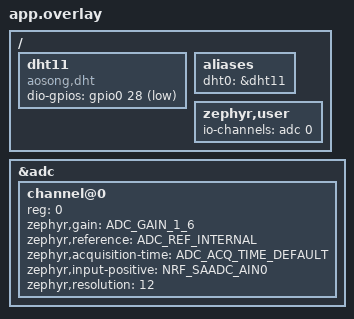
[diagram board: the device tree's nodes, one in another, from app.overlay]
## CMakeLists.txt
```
cmake_minimum_required(VERSION 3.20.0)

find_package(Zephyr REQUIRED HINTS $ENV{ZEPHYR_BASE})
project(sensor_node)

target_include_directories(app PRIVATE include)

target_sources(app PRIVATE
    src/main.c
    src/dht11_sensor.c
    src/sensor_monitor.c
    src/alert.c
    src/mq2_sensor.c
    src/alert_logic.c
)
```

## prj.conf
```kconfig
CONFIG_STDOUT_CONSOLE=y
CONFIG_SENSOR=y
CONFIG_GPIO=y
CONFIG_CBPRINTF_FP_SUPPORT=y
CONFIG_ADC=y
```

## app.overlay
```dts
#include <zephyr/dt-bindings/gpio/gpio.h>
#include <zephyr/dt-bindings/adc/adc.h>

/ {
    dht11: dht11 {
        compatible = "aosong,dht";
        status = "okay";
        dio-gpios = <&gpio0 28 GPIO_ACTIVE_LOW>;
    };

    aliases {
        dht0 = &dht11;
    };

    zephyr,user {
        io-channels = <&adc 0>;
    };
};

&adc {
    status = "okay";

    #address-cells = <1>;
    #size-cells = <0>;

    channel@0 {
        reg = <0>;
        zephyr,gain = "ADC_GAIN_1_6";
        zephyr,reference = "ADC_REF_INTERNAL";
        zephyr,acquisition-time = <ADC_ACQ_TIME_DEFAULT>;
        zephyr,input-positive = <NRF_SAADC_AIN0>;
        zephyr,resolution = <12>;
    };
};
```

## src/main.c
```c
#include <zephyr/kernel.h>
#include <zephyr/sys/printk.h>

int main(void)
{
    return 0;
}
```

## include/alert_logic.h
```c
#ifndef ALERT_LOGIC_H
#define ALERT_LOGIC_H

#include <stdbool.h>
#include "sensor_data.h"

enum alert_level {
    ALERT_NORMAL,
    ALERT_WARNING,
    ALERT_CRITICAL,
    ALERT_UNKNOWN
};

struct alert_result {
    enum alert_level level;

    bool high_temperature;
    bool extreme_temperature;
    bool high_gas;
    bool extreme_gas;
    bool flame_detected;
    bool assessment_complete;
};

struct alert_result evaluate_alert(
    const struct sensor_data *data
);

#endif
```

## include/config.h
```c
#ifndef APP_CONFIG_H
#define APP_CONFIG_H

/* Sensor sampling */
#define SENSOR_INTERVAL_SECONDS 10

#define MQ2_COUNTER 20
#define MQ2_DELAY 20
#define MQ2_MINIMUM_VALID_RFEADINGS 15

/* Temperature thresholds (Celsius) */
#define TEMP_HIGH_THRESHOLD 35.0
#define TEMP_EXTREME_THRESHOLD 55.0

/* Sensor error values */
#define DHT_ERROR_VALUE -1000.0
#define MQ2_ERROR_VALUE -1

/* MQ-2 thresholds (raw ADC values - experimental) */
#define MQ2_HIGH_THRESHOLD 250
#define MQ2_EXTREME_THRESHOLD 400

/* Flame detection*/
#define FLAME_ERROR_VALUE -1
#define FLAME_NOT_DETECTED 0
#define FLAME_DETECTED 1

#endif
```

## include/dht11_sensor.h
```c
#ifndef DHT11_SENSOR_H
#define DHT11_SENSOR_H

#include "sensor_data.h"

int dht11_read(struct sensor_data *data);

#endif
```

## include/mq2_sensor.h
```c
#ifndef MQ2_SENSOR_H
#define MQ2_SENSOR_H

int mq2_init(void);
int mq2_read(int *raw_value);

#endif
```

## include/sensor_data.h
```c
#ifndef SENSOR_DATA_H
#define SENSOR_DATA_H

#include <zephyr/kernel.h>

struct sensor_data {
    double temperature;
    double humidity;
    int mq2_raw;
    int flame_detected;
};

extern struct k_msgq sensor_queue;

#endif
```

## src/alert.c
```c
#include <zephyr/kernel.h>
#include <zephyr/sys/printk.h>

#include "sensor_data.h"
#include "alert_logic.h"
#include "config.h"

void alert_thread(void)
{
    struct sensor_data data;

    while (1) {
        if (k_msgq_get(&sensor_queue, &data, K_FOREVER) != 0) {
            continue;
        }

        bool dht_ok = (data.temperature != DHT_ERROR_VALUE);
        bool mq2_ok = (data.mq2_raw != MQ2_ERROR_VALUE);
        bool flame_ok =
            (data.flame_detected != FLAME_ERROR_VALUE);
        
            struct alert_result result = evaluate_alert(&data);

        const char *status;

        switch (result.level) {
        case ALERT_NORMAL:
            status = "NORMAL";
            break;
        case ALERT_WARNING:
            status = "WARNING";
            break;
        case ALERT_CRITICAL:
            status = "CRITICAL";
            break;
        default:
            status = "UNKNOWN";
            break;
        }

        /* Display sensor measurements */
        if (dht_ok) {
            printk("🌡️:%.2f 💧:%.2f ",
                   data.temperature, data.humidity);
        } else {
            printk("🌡️:N/A 💧:N/A ");
        }

        if (mq2_ok) {
            printk("💨:%d ", data.mq2_raw);
        } else {
            printk("💨:N/A ");
        }

        if (flame_ok) {
            printk("🔥:%d ", data.flame_detected);
        } else {
            printk("🔥:N/A ");
        }

        printk("S:%s R:", status);

        /* Display alert reasons */
        bool has_reason = false;

        if (result.extreme_temperature) {
            printk("EXTREME_TEMP");
            has_reason = true;
        } else if (result.high_temperature) {
            printk("HIGH_TEMP");
            has_reason = true;
        }

        if (result.extreme_gas) {
            printk("%sEXTREME_GAS", has_reason ? "," : "");
            has_reason = true;
        } else if (result.high_gas) {
            printk("%sHIGH_GAS", has_reason ? "," : "");
            has_reason = true;
        }

        if (result.flame_detected) {
            printk("%sFLAME", has_reason ? "," : "");
            has_reason = true;
        }

        if (!has_reason) {
            printk("NONE");
        }

        printk("\n");
    }
}

K_THREAD_DEFINE(alert_tid, 1024, alert_thread,
                NULL, NULL, NULL, 5, 0, 0);
```

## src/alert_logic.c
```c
#include "alert_logic.h"
#include "config.h"

struct alert_result evaluate_alert(
    const struct sensor_data *data)
{
    struct alert_result result = {
        .level = ALERT_UNKNOWN,
        .assessment_complete = false
    };

    /* Temperature */
    if (data->temperature != DHT_ERROR_VALUE) {
        result.high_temperature =
            data->temperature >= TEMP_HIGH_THRESHOLD;

        result.extreme_temperature =
            data->temperature >= TEMP_EXTREME_THRESHOLD;
    }

    /* Gas */
    if (data->mq2_raw != MQ2_ERROR_VALUE) {
        result.high_gas =
            data->mq2_raw >= MQ2_HIGH_THRESHOLD;

        result.extreme_gas =
            data->mq2_raw >= MQ2_EXTREME_THRESHOLD;
    }

    /* Flame */
    result.flame_detected =
        (data->flame_detected == FLAME_DETECTED);

    /* Check if all sensors provided valid measurements */
    result.assessment_complete =
        (data->temperature != DHT_ERROR_VALUE) &&
        (data->mq2_raw != MQ2_ERROR_VALUE) &&
        (data->flame_detected == FLAME_NOT_DETECTED ||
         data->flame_detected == FLAME_DETECTED);

    /* Count distinct hazard categories */
    int danger_count =
        (result.high_temperature || result.extreme_temperature) +
        (result.high_gas || result.extreme_gas) +
        result.flame_detected;

    /* Determine alert level */
    if (result.flame_detected || danger_count >= 2) {
        result.level = ALERT_CRITICAL;
    } else if (danger_count == 1) {
        result.level = ALERT_WARNING;
    } else if (result.assessment_complete) {
        result.level = ALERT_NORMAL;
    }

    return result;
}
```

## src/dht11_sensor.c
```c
#include <zephyr/device.h>
#include <zephyr/drivers/sensor.h>
#include <errno.h>

#include "dht11_sensor.h"
#include "sensor_data.h"

#define DHT_NODE DT_ALIAS(dht0)

int dht11_read(struct sensor_data *data)
{
    const struct device *dht = DEVICE_DT_GET(DHT_NODE);
    struct sensor_value temp, hum;

    if (!device_is_ready(dht)) {
        return -ENODEV;
    }

    int ret = sensor_sample_fetch(dht);
    if (ret != 0) {
        return ret;
    }

    ret = sensor_channel_get(dht, SENSOR_CHAN_AMBIENT_TEMP, &temp);
    if (ret != 0) {
        return ret;
    }

    ret = sensor_channel_get(dht, SENSOR_CHAN_HUMIDITY, &hum);
    if (ret != 0) {
        return ret;
    }

    data->temperature = temp.val1+temp.val2 / 1000000.0;
    data->humidity = hum.val1+hum.val2 / 1000000.0;

    return 0;
}
```

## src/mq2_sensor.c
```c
#include <zephyr/device.h>
#include <zephyr/drivers/adc.h>
#include <zephyr/kernel.h>
#include <errno.h>
#include <stdint.h>

#include "mq2_sensor.h"
#include "config.h"

#define ADC_NODE DT_PATH(zephyr_user)

static const struct adc_dt_spec mq2_adc =
    ADC_DT_SPEC_GET_BY_IDX(ADC_NODE, 0);

int mq2_init(void)
{
    if (!adc_is_ready_dt(&mq2_adc)) {
        return -ENODEV;
    }

    return adc_channel_setup_dt(&mq2_adc);
}


int mq2_read(int *raw_value)
{
    int32_t sum = 0;
    int valid_count = 0;

    for (int i = 0; i < MQ2_COUNTER; i++) {
        int16_t sample = 0;

        struct adc_sequence sequence = {
            .buffer = &sample,
            .buffer_size = sizeof(sample),
        };

        int ret = adc_sequence_init_dt(&mq2_adc, &sequence);

        if (ret != 0) {
            return ret;
        }

        ret = adc_read_dt(&mq2_adc, &sequence);

        if (ret == 0) {
            sum += sample;
            valid_count++;
        }

        if (i < MQ2_COUNTER - 1) {
            k_msleep(MQ2_DELAY);
        }
    }

    if (valid_count < MQ2_MINIMUM_VALID_RFEADINGS) {
        return -EIO;
    }

    *raw_value = sum / valid_count;

    return 0;
}
```

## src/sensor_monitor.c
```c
#include <zephyr/kernel.h>

#include "sensor_data.h"
#include "dht11_sensor.h"
#include "mq2_sensor.h"
#include "config.h"

K_MSGQ_DEFINE(sensor_queue, sizeof(struct sensor_data), 10, 4);

void sensor_thread(void)
{
    struct sensor_data data;
    bool mq2_ready = (mq2_init() == 0);

    while (1) {
        data.temperature = DHT_ERROR_VALUE;
        data.humidity = DHT_ERROR_VALUE;
        data.mq2_raw = MQ2_ERROR_VALUE;
        data.flame_detected= FLAME_ERROR_VALUE;

        if (dht11_read(&data) != 0) {
            data.temperature = DHT_ERROR_VALUE;
            data.humidity = DHT_ERROR_VALUE;
        }

        if (mq2_ready) {
            if (mq2_read(&data.mq2_raw) != 0) {
                data.mq2_raw = MQ2_ERROR_VALUE;
            }
        }

        k_msgq_put(&sensor_queue, &data, K_NO_WAIT);

        k_sleep(K_SECONDS(SENSOR_INTERVAL_SECONDS));
    }
}

K_THREAD_DEFINE(sensor_tid, 2048, sensor_thread,
                NULL, NULL, NULL, 5, 0, 0);
```
